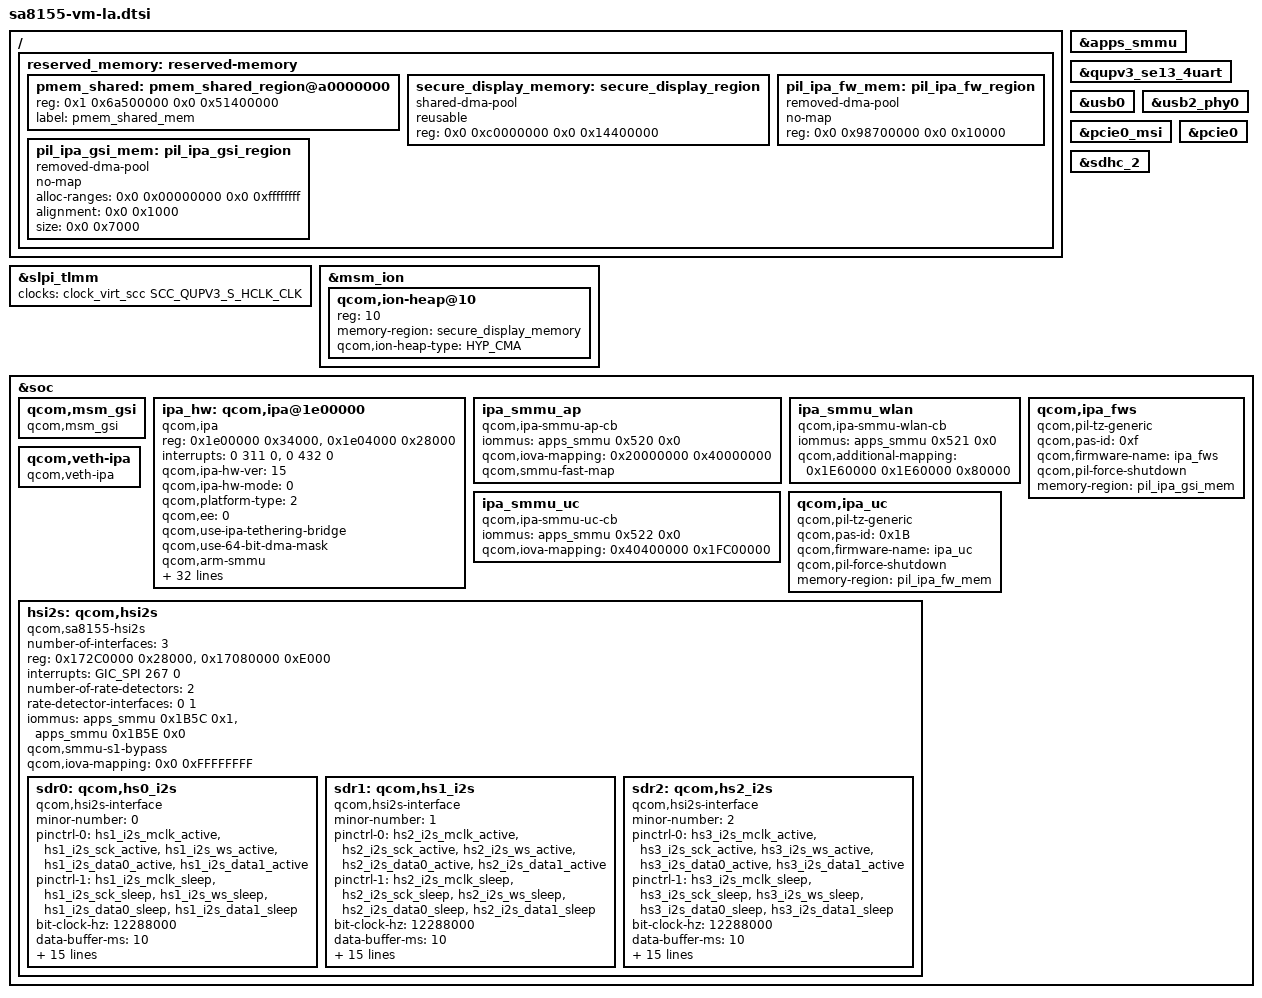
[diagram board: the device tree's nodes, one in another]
/*
 * Copyright (c) 2020, The Linux Foundation. All rights reserved.

 * This program is free software; you can redistribute it and/or modify
 * it under the terms of the GNU General Public License version 2 and
 * only version 2 as published by the Free Software Foundation.

 * This program is distributed in the hope that it will be useful,
 * but WITHOUT ANY WARRANTY; without even the implied warranty of
 * MERCHANTABILITY or FITNESS FOR A PARTICULAR PURPOSE.  See the
 * GNU General Public License for more details.
 */

#include <dt-bindings/msm/msm-bus-ids.h>

/ {
	reserved_memory: reserved-memory {

		pmem_shared: pmem_shared_region@a0000000 {
			reg = <0x1 0x6a500000 0x0 0x51400000>;
			label = "pmem_shared_mem";
		};

		secure_display_memory: secure_display_region { /* Secure UI */
			compatible = "shared-dma-pool";
			reusable;
			reg = <0x0 0xc0000000 0x0 0x14400000>;
		};

		pil_ipa_fw_mem: pil_ipa_fw_region {
			compatible = "removed-dma-pool";
			no-map;
			reg = <0x0 0x98700000 0x0 0x10000>;
		};

		pil_ipa_gsi_mem: pil_ipa_gsi_region {
			compatible = "removed-dma-pool";
			no-map;
			alloc-ranges = <0x0 0x00000000 0x0 0xffffffff>;
			alignment = <0x0 0x1000>;
			size = <0x0 0x7000>;
		};
	};
};

&slpi_tlmm {
	clocks =  <&clock_virt_scc SCC_QUPV3_S_HCLK_CLK>;
	status = "ok";
};

&apps_smmu {
	status = "ok";
};

&qupv3_se13_4uart {
	status = "ok";
};

&usb0 {
	status = "ok";
};

&usb2_phy0 {
	status = "ok";
};

&pcie0_msi {
	status = "ok";
};

&pcie0 {
	status = "ok";
};

&sdhc_2 {
	status = "ok";
};

&msm_ion {
	qcom,ion-heap@10 { /* SECURE DISPLAY HEAP */
		reg = <10>;
		memory-region = <&secure_display_memory>;
		qcom,ion-heap-type = "HYP_CMA";
	};
};

&soc {
	qcom,msm_gsi {
		compatible = "qcom,msm_gsi";
	};

	ipa_hw: qcom,ipa@1e00000 {
		compatible = "qcom,ipa";
		reg = <0x1e00000 0x34000>,
		      <0x1e04000 0x28000>;
		reg-names = "ipa-base", "gsi-base";
		interrupts =
			<0 311 0>,
			<0 432 0>;
		interrupt-names = "ipa-irq", "gsi-irq";
		qcom,ipa-hw-ver = <15>; /* IPA core version = IPAv4.1 */
		qcom,ipa-hw-mode = <0>;
		qcom,platform-type = <2>; /* APQ platform */
		qcom,ee = <0>;
		qcom,use-ipa-tethering-bridge;
		qcom,use-64-bit-dma-mask;
		qcom,arm-smmu;
		qcom,use-ipa-pm;
		qcom,bandwidth-vote-for-ipa;
		qcom,register-collection-on-crash;
		qcom,manual-fw-load;
		qcom,msm-bus,name = "ipa";
		qcom,msm-bus,num-cases = <5>;
		qcom,msm-bus,num-paths = <4>;
		qcom,msm-bus,vectors-KBps =
		/* No vote */
		<MSM_BUS_MASTER_IPA MSM_BUS_SLAVE_EBI_CH0 0 0>,
		<MSM_BUS_MASTER_IPA MSM_BUS_SLAVE_OCIMEM 0 0>,
		<MSM_BUS_MASTER_AMPSS_M0 MSM_BUS_SLAVE_IPA_CFG 0 0>,
		<MSM_BUS_MASTER_IPA_CORE MSM_BUS_SLAVE_IPA_CORE 0 0>,

		/* SVS2 */
		<MSM_BUS_MASTER_IPA MSM_BUS_SLAVE_EBI_CH0 80000 600000>,
		<MSM_BUS_MASTER_IPA MSM_BUS_SLAVE_OCIMEM 80000 350000>,
		<MSM_BUS_MASTER_AMPSS_M0 MSM_BUS_SLAVE_IPA_CFG 40000 40000>,
		<MSM_BUS_MASTER_IPA_CORE MSM_BUS_SLAVE_IPA_CORE 0 125>,

		/* SVS */
		<MSM_BUS_MASTER_IPA MSM_BUS_SLAVE_EBI_CH0 80000 640000>,
		<MSM_BUS_MASTER_IPA MSM_BUS_SLAVE_OCIMEM 80000 640000>,
		<MSM_BUS_MASTER_AMPSS_M0 MSM_BUS_SLAVE_IPA_CFG 80000 80000>,
		<MSM_BUS_MASTER_IPA_CORE MSM_BUS_SLAVE_IPA_CORE 0 250>,

		/* NOMINAL */
		<MSM_BUS_MASTER_IPA MSM_BUS_SLAVE_EBI_CH0 206000 960000>,
		<MSM_BUS_MASTER_IPA MSM_BUS_SLAVE_OCIMEM 206000 960000>,
		<MSM_BUS_MASTER_AMPSS_M0 MSM_BUS_SLAVE_IPA_CFG 206000 160000>,
		<MSM_BUS_MASTER_IPA_CORE MSM_BUS_SLAVE_IPA_CORE 0 500>,

		/* TURBO */
		<MSM_BUS_MASTER_IPA MSM_BUS_SLAVE_EBI_CH0 206000 3600000>,
		<MSM_BUS_MASTER_IPA MSM_BUS_SLAVE_OCIMEM 206000 3600000>,
		<MSM_BUS_MASTER_AMPSS_M0 MSM_BUS_SLAVE_IPA_CFG 206000 300000>,
		<MSM_BUS_MASTER_IPA_CORE MSM_BUS_SLAVE_IPA_CORE 0 600>;

		qcom,bus-vector-names = "MIN", "SVS2", "SVS", "NOMINAL",
		"TURBO";
		qcom,throughput-threshold = <310 600 1000>;
		qcom,scaling-exceptions = <>;
	};

	ipa_smmu_ap: ipa_smmu_ap {
		compatible = "qcom,ipa-smmu-ap-cb";
		iommus = <&apps_smmu 0x520 0x0>;
		qcom,iova-mapping = <0x20000000 0x40000000>;
		qcom,smmu-fast-map;
	};

	ipa_smmu_wlan: ipa_smmu_wlan {
		compatible = "qcom,ipa-smmu-wlan-cb";
		iommus = <&apps_smmu 0x521 0x0>;
		qcom,additional-mapping =
		/* ipa-uc ram */
		<0x1E60000 0x1E60000 0x80000>;
	};

	ipa_smmu_uc: ipa_smmu_uc {
		compatible = "qcom,ipa-smmu-uc-cb";
		iommus = <&apps_smmu 0x522 0x0>;
		qcom,iova-mapping = <0x40400000 0x1FC00000>;
	};

	qcom,ipa_fws {
		compatible = "qcom,pil-tz-generic";
		qcom,pas-id = <0xf>;
		qcom,firmware-name = "ipa_fws";
		qcom,pil-force-shutdown;
		memory-region = <&pil_ipa_gsi_mem>;
	};

	qcom,ipa_uc {
		compatible = "qcom,pil-tz-generic";
		qcom,pas-id = <0x1B>;
		qcom,firmware-name = "ipa_uc";
		qcom,pil-force-shutdown;
		memory-region = <&pil_ipa_fw_mem>;
	};

	qcom,veth-ipa {
		compatible = "qcom,veth-ipa";
	};

	hsi2s: qcom,hsi2s {
		compatible = "qcom,sa8155-hsi2s", "qcom,hsi2s";
		number-of-interfaces = <3>;
		reg = <0x172C0000 0x28000>,
		      <0x17080000 0xE000>;
		reg-names = "lpa_if", "lpass_tcsr";
		interrupts = <GIC_SPI 267 0>;
		number-of-rate-detectors = <2>;
		rate-detector-interfaces = <0 1>;
		iommus = <&apps_smmu 0x1B5C 0x1>,
			 <&apps_smmu 0x1B5E 0x0>;
		qcom,smmu-s1-bypass;
		qcom,iova-mapping = <0x0 0xFFFFFFFF>;

		sdr0: qcom,hs0_i2s {
			compatible = "qcom,hsi2s-interface";
			minor-number = <0>;
			pinctrl-names = "default", "sleep";
			pinctrl-0 = <&hs1_i2s_mclk_active &hs1_i2s_sck_active
				     &hs1_i2s_ws_active &hs1_i2s_data0_active
				     &hs1_i2s_data1_active>;
			pinctrl-1 = <&hs1_i2s_mclk_sleep &hs1_i2s_sck_sleep
				     &hs1_i2s_ws_sleep &hs1_i2s_data0_sleep
				     &hs1_i2s_data1_sleep>;
			bit-clock-hz = <12288000>;
			data-buffer-ms = <10>;
			bit-depth = <32>;
			spkr-channel-count = <2>;
			mic-channel-count = <2>;
			pcm-rate = <2>;
			pcm-sync-src = <0>;
			aux-mode = <0>;
			rpcm-width = <1>;
			tpcm-width = <1>;
			enable-tdm = <1>;
			tdm-rate = <32>;
			tdm-rpcm-width = <16>;
			tdm-tpcm-width = <16>;
			tdm-sync-delay = <2>;
			tdm-inv-sync = <0>;
			pcm-lane-config = <1>;
		};

		sdr1: qcom,hs1_i2s {
			compatible = "qcom,hsi2s-interface";
			minor-number = <1>;
			pinctrl-names = "default", "sleep";
			pinctrl-0 = <&hs2_i2s_mclk_active &hs2_i2s_sck_active
				     &hs2_i2s_ws_active &hs2_i2s_data0_active
				     &hs2_i2s_data1_active>;
			pinctrl-1 = <&hs2_i2s_mclk_sleep &hs2_i2s_sck_sleep
				     &hs2_i2s_ws_sleep &hs2_i2s_data0_sleep
				     &hs2_i2s_data1_sleep>;
			bit-clock-hz = <12288000>;
			data-buffer-ms = <10>;
			bit-depth = <32>;
			spkr-channel-count = <2>;
			mic-channel-count = <2>;
			pcm-rate = <2>;
			pcm-sync-src = <0>;
			aux-mode = <0>;
			rpcm-width = <1>;
			tpcm-width = <1>;
			enable-tdm = <1>;
			tdm-rate = <32>;
			tdm-rpcm-width = <16>;
			tdm-tpcm-width = <16>;
			tdm-sync-delay = <2>;
			tdm-inv-sync = <0>;
			pcm-lane-config = <1>;
		};

		sdr2: qcom,hs2_i2s {
			compatible = "qcom,hsi2s-interface";
			minor-number = <2>;
			pinctrl-names = "default", "sleep";
			pinctrl-0 = <&hs3_i2s_mclk_active &hs3_i2s_sck_active
				     &hs3_i2s_ws_active &hs3_i2s_data0_active
				     &hs3_i2s_data1_active>;
			pinctrl-1 = <&hs3_i2s_mclk_sleep &hs3_i2s_sck_sleep
				     &hs3_i2s_ws_sleep &hs3_i2s_data0_sleep
				     &hs3_i2s_data1_sleep>;
			bit-clock-hz = <12288000>;
			data-buffer-ms = <10>;
			bit-depth = <32>;
			spkr-channel-count = <2>;
			mic-channel-count = <2>;
			pcm-rate = <2>;
			pcm-sync-src = <0>;
			aux-mode = <0>;
			rpcm-width = <1>;
			tpcm-width = <1>;
			enable-tdm = <1>;
			tdm-rate = <32>;
			tdm-rpcm-width = <16>;
			tdm-tpcm-width = <16>;
			tdm-sync-delay = <2>;
			tdm-inv-sync = <0>;
			pcm-lane-config = <1>;
		};
	};
};
